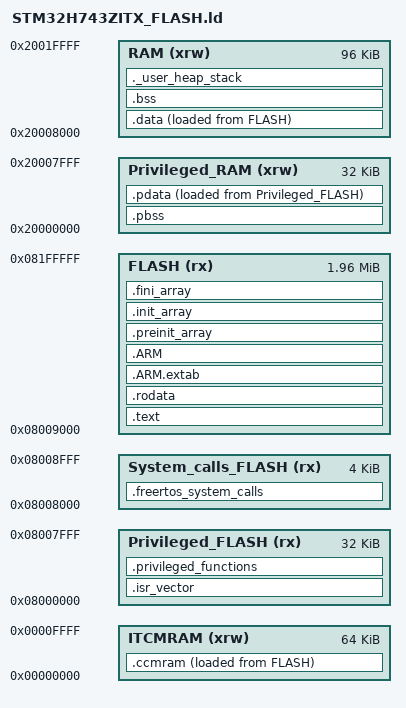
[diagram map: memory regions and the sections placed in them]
/*
******************************************************************************
**
** @file        : LinkerScript.ld
**
** @author      : Auto-generated by STM32CubeIDE
**
**  Abstract    : Linker script for NUCLEO-H743ZI Board embedding STM32H743ZITx Device from stm32h7 series
**                      32Kbytes ROM_privileged
**                      4Kbytes ROM_system_calls
**                      2012Kbytes ROM_unprivileged
**                      64Kbytes ITCMRAM
**                      32Kbytes RAM_privileged
**                      96Kbytes RAM_unprivileged
**
**                Set heap size, stack size and stack location according
**                to application requirements.
**
**                Set memory bank area and size if external memory is used
**
**  Target      : STMicroelectronics STM32
**
**  Distribution: The file is distributed as is, without any warranty
**                of any kind.
**
******************************************************************************
** @attention
**
** Copyright (c) 2022 STMicroelectronics.
** All rights reserved.
**
** This software is licensed under terms that can be found in the LICENSE file
** in the root directory of this software component.
** If no LICENSE file comes with this software, it is provided AS-IS.
**
******************************************************************************
*/
/* Entry Point */
ENTRY(Reset_Handler)

/* Highest address of the user mode stack */
_estack = 0x2001FFFF;    /* end of RAM */
/* Generate a link error if heap and stack don't fit into RAM */
_Min_Heap_Size = 0x200;      /* required amount of heap  */
_Min_Stack_Size = 0x400; /* required amount of stack */

 
/* Specify the memory areas */
MEMORY
{
FLASH (rx)      : ORIGIN = 0x08009000, LENGTH = 2012K
Privileged_FLASH (rx)      : ORIGIN = 0x08000000, LENGTH = 32K
System_calls_FLASH (rx)      : ORIGIN = 0x08008000, LENGTH = 4K
RAM (xrw)      : ORIGIN = 0x20008000, LENGTH = 96K
Privileged_RAM (xrw)      : ORIGIN = 0x20000000, LENGTH = 32K
ITCMRAM (xrw)      : ORIGIN = 0x00000000, LENGTH = 64K
}

/* Variables used by FreeRTOS-MPU. */
_Privileged_Functions_Region_Size = 32K;
_system_calls_Region_Size = 4K;
_Privileged_Data_Region_Size = 32K;

__FLASH_segment_start__ = ORIGIN( Privileged_FLASH );
__FLASH_segment_end__ = __FLASH_segment_start__ + LENGTH( Privileged_FLASH ) + LENGTH( System_calls_FLASH ) + LENGTH( FLASH );

__privileged_functions_start__ = ORIGIN( Privileged_FLASH );
__privileged_functions_end__ = __privileged_functions_start__ + _Privileged_Functions_Region_Size;

__SRAM_segment_start__ = ORIGIN( Privileged_RAM );
__SRAM_segment_end__ = __SRAM_segment_start__ + LENGTH( Privileged_RAM ) + LENGTH( RAM );

__privileged_data_start__ = ORIGIN( Privileged_RAM );
__privileged_data_end__ = __privileged_data_start__ + _Privileged_Data_Region_Size;

__syscalls_flash_start__ = ORIGIN( System_calls_FLASH );
__syscalls_flash_end__ = __syscalls_flash_start__ + _system_calls_Region_Size;

/* Define output sections */
SECTIONS
{
  /* The startup code goes first into FLASH */
  .isr_vector :
  {
    . = ALIGN(4);
    KEEP(*(.isr_vector)) /* Startup code */
    . = ALIGN(4);
  } >Privileged_FLASH
  
    .privileged_functions : 
  {
    . = ALIGN(4);
    *(privileged_functions)
    *(privileged_functions*)
    . = ALIGN(4);
  } >Privileged_FLASH
  
    .freertos_system_calls : 
  {
    . = ALIGN(4);
    *(freertos_system_calls)
    *(freertos_system_calls*)
    . = ALIGN(4);
  } >System_calls_FLASH

  /* The program code and other data goes into FLASH */
  .text :
  {
    . = ALIGN(4);
    *(.text)           /* .text sections (code) */
    *(.text*)          /* .text* sections (code) */
    *(.glue_7)         /* glue arm to thumb code */
    *(.glue_7t)        /* glue thumb to arm code */
    *(.eh_frame)

    KEEP (*(.init))
    KEEP (*(.fini))

    . = ALIGN(4);
    _etext = .;        /* define a global symbols at end of code */
  } >FLASH

  /* Constant data goes into FLASH */
  .rodata :
  {
    . = ALIGN(4);
    *(.rodata)         /* .rodata sections (constants, strings, etc.) */
    *(.rodata*)        /* .rodata* sections (constants, strings, etc.) */
    . = ALIGN(4);
  } >FLASH

  .ARM.extab (READONLY) : /* The READONLY keyword is only supported in GCC11 and later, remove it if using GCC10 or earlier. */
  {
    *(.ARM.extab* .gnu.linkonce.armextab.*)
  } >FLASH
  .ARM (READONLY) : /* The READONLY keyword is only supported in GCC11 and later, remove it if using GCC10 or earlier. */
  {
    __exidx_start = .;
    *(.ARM.exidx*)
    __exidx_end = .;
  } >FLASH

  .preinit_array (READONLY) : /* The READONLY keyword is only supported in GCC11 and later, remove it if using GCC10 or earlier. */
  {
    PROVIDE_HIDDEN (__preinit_array_start = .);
    KEEP (*(.preinit_array*))
    PROVIDE_HIDDEN (__preinit_array_end = .);
  } >FLASH
  .init_array (READONLY) : /* The READONLY keyword is only supported in GCC11 and later, remove it if using GCC10 or earlier. */
  {
    PROVIDE_HIDDEN (__init_array_start = .);
    KEEP (*(SORT(.init_array.*)))
    KEEP (*(.init_array*))
    PROVIDE_HIDDEN (__init_array_end = .);
  } >FLASH
  .fini_array (READONLY) : /* The READONLY keyword is only supported in GCC11 and later, remove it if using GCC10 or earlier. */
  {
    PROVIDE_HIDDEN (__fini_array_start = .);
    KEEP (*(SORT(.fini_array.*)))
    KEEP (*(.fini_array*))
    PROVIDE_HIDDEN (__fini_array_end = .);
  } >FLASH

.pbss : 
  {
    . = ALIGN(4);
    _spbss = .;
    *(privileged_data)
    *(privileged_data*)
    . = ALIGN(4);
    _epbss = .;
  } >Privileged_RAM
 
  /* used by the startup to initialize data */
  _sipdata = LOADADDR(.pdata);

  .pdata : 
  {
    . = ALIGN(4);
    _spdata = .;
    *(privileged_data)
    *(privileged_data*)
    . = ALIGN(4);
    _epdata = .;
  } >Privileged_RAM AT> Privileged_FLASH

  /* used by the startup to initialize data */
  _sidata = LOADADDR(.data);

  /* Initialized data sections goes into RAM, load LMA copy after code */
  .data : 
  {
    . = ALIGN(4);
    _sdata = .;        /* create a global symbol at data start */
    *(.data)           /* .data sections */
    *(.data*)          /* .data* sections */

    . = ALIGN(4);
    _edata = .;        /* define a global symbol at data end */
  } >RAM AT> FLASH

  _siccmram = LOADADDR(.ccmram);

  /* CCM-RAM section 
  * 
  * IMPORTANT NOTE! 
  * If initialized variables will be placed in this section,
  * the startup code needs to be modified to copy the init-values.  
  */
  .ccmram :
  {
    . = ALIGN(4);
    _sccmram = .;       /* create a global symbol at ccmram start */
    *(.ccmram)
    *(.ccmram*)
    
    . = ALIGN(4);
    _eccmram = .;       /* create a global symbol at ccmram end */
  } >ITCMRAM AT> FLASH

  
  /* Uninitialized data section */
  . = ALIGN(4);
  .bss :
  {
    /* This is used by the startup in order to initialize the .bss section */
    _sbss = .;         /* define a global symbol at bss start */
    __bss_start__ = _sbss;
    *(.bss)
    *(.bss*)
    *(COMMON)

    . = ALIGN(4);
    _ebss = .;         /* define a global symbol at bss end */
    __bss_end__ = _ebss;
  } >RAM

  /* User_heap_stack section, used to check that there is enough RAM left */
  ._user_heap_stack :
  {
    . = ALIGN(8);
    PROVIDE ( end = . );
    PROVIDE ( _end = . );
    . = . + _Min_Heap_Size;
    . = . + _Min_Stack_Size;
    . = ALIGN(8);
  } >RAM

  

  /* Remove information from the standard libraries */
  /DISCARD/ :
  {
    libc.a ( * )
    libm.a ( * )
    libgcc.a ( * )
  }

  .ARM.attributes 0 : { *(.ARM.attributes) }
}

